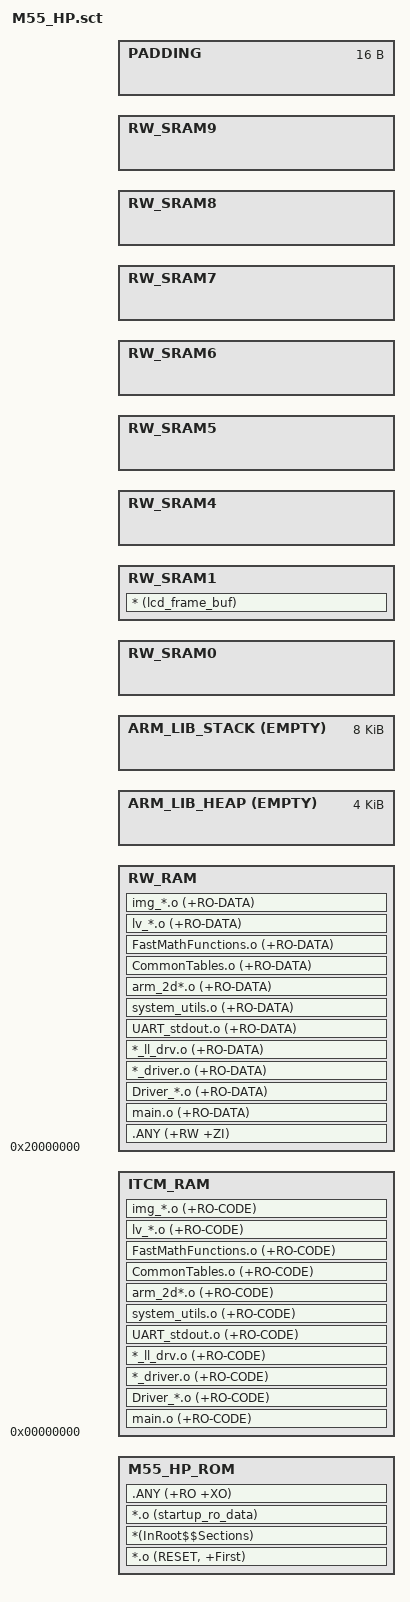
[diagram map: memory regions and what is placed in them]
#! armclang -E --target=arm-arm-none-eabi -mcpu=cortex-m55 -xc
; command above MUST be in first line (no comment above!)
#include "M55_HP_map.h"
#include "app_map.h"

/* MRAM code storage for M55-HP */
#define __ROM_BASE      _APP_ADDRESS
#define __ROM_SIZE      _APP_MAX_SIZE

/* SRAM2 is mapped as ITCM in M55-HP */
#define __ITCM_BASE     0x00000000
#define __ITCM_SIZE     SRAM2_SIZE

/* SRAM3 is mapped as DTCM in M55-HP */
#define __RAM_BASE      0x20000000
#define __RAM_SIZE      SRAM3_SIZE

#define __STACK_SIZE    0x00002000
#define __HEAP_SIZE     0x00001000

/*----------------------------------------------------------------------------
  User Stack & Heap boundary definition
 *----------------------------------------------------------------------------*/
#define __STACK_TOP     (__RAM_BASE + __RAM_SIZE)    /* starts at end of RAM */
#define __HEAP_BASE     (AlignExpr(+0, 8))           /* starts after RW_RAM section, 8 byte aligned */

/*----------------------------------------------------------------------------
  Scatter File Definitions definition
 *----------------------------------------------------------------------------*/

#define __RW_BASE       __RAM_BASE
#define __RW_SIZE      (__RAM_SIZE - __STACK_SIZE - __HEAP_SIZE - NS_REGION_0_SIZE)

LR_ROM __ROM_BASE __ROM_SIZE {
	M55_HP_ROM +0 __ROM_SIZE {
		*.o (RESET, +First)
		*(InRoot$$Sections)
		*.o (startup_ro_data)
		.ANY (+RO +XO)
	}

	ITCM_RAM __ITCM_BASE __ITCM_SIZE {
		main.o (+RO-CODE)
		Driver_*.o (+RO-CODE)
		*_driver.o (+RO-CODE)
		*_ll_drv.o (+RO-CODE)
		UART_stdout.o (+RO-CODE)
		system_utils.o (+RO-CODE)

		arm_2d*.o (+RO-CODE)
		CommonTables.o (+RO-CODE)
		FastMathFunctions.o (+RO-CODE)

		lv_*.o (+RO-CODE)
		img_*.o (+RO-CODE)
	}

	RW_RAM __RW_BASE __RW_SIZE {
		.ANY (+RW +ZI)

		main.o (+RO-DATA)
		Driver_*.o (+RO-DATA)
		*_driver.o (+RO-DATA)
		*_ll_drv.o (+RO-DATA)
		UART_stdout.o (+RO-DATA)
		system_utils.o (+RO-DATA)

		arm_2d*.o (+RO-DATA)
		CommonTables.o (+RO-DATA)
		FastMathFunctions.o (+RO-DATA)

		lv_*.o (+RO-DATA)
		img_*.o (+RO-DATA)
	}

	ARM_LIB_HEAP  __HEAP_BASE EMPTY  __HEAP_SIZE  { }
	ARM_LIB_STACK __STACK_TOP EMPTY -__STACK_SIZE { }

;	NS_REGION_0  NS_REGION_0_BASE  NS_REGION_0_SIZE { * (eth_buf) }

	RW_SRAM0 SRAM0_BASE SRAM0_SIZE  {
;		lv_*.o (+RO)
;		img_*.o (+RO)
	}
	RW_SRAM1 SRAM1_BASE SRAM1_SIZE  { * (lcd_frame_buf) }
	RW_SRAM4 SRAM4_BASE SRAM4_SIZE  { }
	RW_SRAM5 SRAM5_BASE SRAM5_SIZE  { }
	RW_SRAM6 SRAM6_BASE SRAM6_SIZE  { }
	RW_SRAM7 SRAM7_BASE SRAM7_SIZE  { }
	RW_SRAM8 SRAM8_BASE SRAM8_SIZE  { }
	RW_SRAM9 SRAM9_BASE SRAM9_SIZE  { }

	PADDING +0 ALIGN 16 FILL 0 16 { }
}
#if 0
LR_PARTITION _PARTITION_ADDRESS  _PARTITION_SIZE {
	RESERVED +0 FILL 0 (_PARTITION_SIZE - 16) {}
	ATOC +0 16 { *(:gdef:__mram_atoc) }
}
#endif
